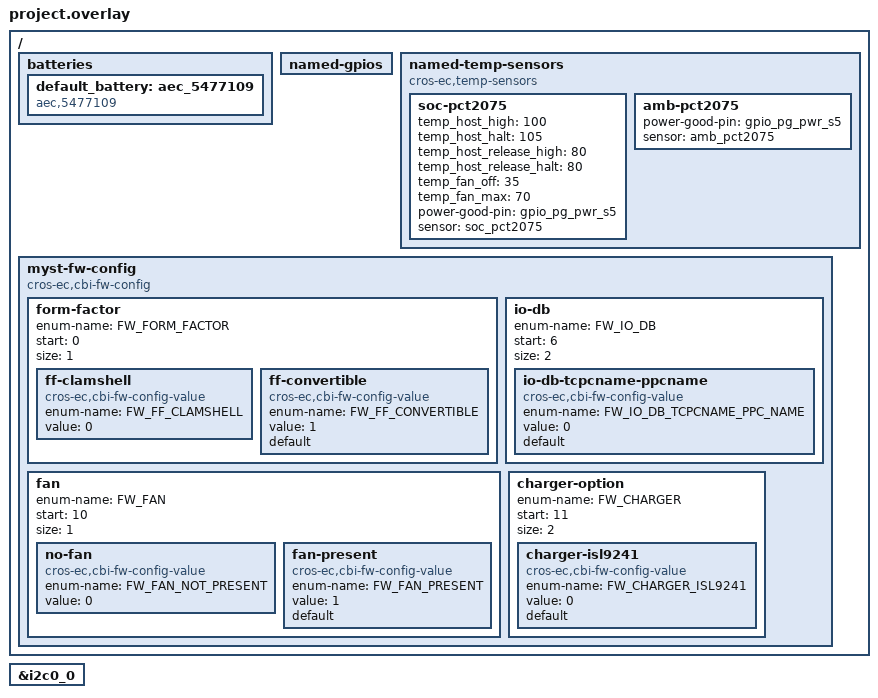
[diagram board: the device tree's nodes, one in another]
/* Copyright 2023 The ChromiumOS Authors
 * Use of this source code is governed by a BSD-style license that can be
 * found in the LICENSE file.
 */

/* Myst program common DTS includes */
#include "../adc.dtsi"
#include "../fan.dtsi"
#include "../gpio.dtsi"
#include "../i2c.dtsi"
#include "../interrupts.dtsi"
#include "../keyboard.dtsi"
#include "../usbc.dtsi"

/* Myst project DTS includes*/
#include "led_pins.dtsi"
#include "led_policy.dtsi"

/* Myst overrides follow... */
/ {
	/* battery overrides */
	batteries {
		default_battery: aec_5477109 {
			compatible = "aec,5477109", "battery-smart";
		};
	};

	named-gpios {
		/* Myst-specific GPIO customizations */
	};

	named-temp-sensors {
		compatible = "cros-ec,temp-sensors";
		soc-pct2075 {
			temp_host_high = <100>;
			temp_host_halt = <105>;
			temp_host_release_high = <80>;
			temp_host_release_halt = <80>;
			temp_fan_off = <35>;
			temp_fan_max = <70>;
			power-good-pin = <&gpio_pg_pwr_s5>;
			sensor = <&soc_pct2075>;
		};
		amb-pct2075 {
			power-good-pin = <&gpio_pg_pwr_s5>;
			sensor = <&amb_pct2075>;
		};
	};

	/*
	 * Note this is expected to vary per-board, so we keep it in the overlay
	 * files.
	 */
	myst-fw-config {
		compatible = "cros-ec,cbi-fw-config";

		form-factor {
			enum-name = "FW_FORM_FACTOR";
			start = <0>;
			size = <1>;

			ff-clamshell {
				compatible = "cros-ec,cbi-fw-config-value";
				enum-name = "FW_FF_CLAMSHELL";
				value = <0>;
			};
			ff-convertible {
				compatible = "cros-ec,cbi-fw-config-value";
				enum-name = "FW_FF_CONVERTIBLE";
				value = <1>;
				default;
			};
		};
		io-db {
			enum-name = "FW_IO_DB";
			start = <6>;
			size = <2>;

			io-db-tcpcname-ppcname {
				compatible = "cros-ec,cbi-fw-config-value";
				enum-name = "FW_IO_DB_TCPCNAME_PPC_NAME";
				value = <0>;
                                default;
			};
		};

		/*
		 * FW_CONFIG field to enable fan or not.
		 */
		fan {
			enum-name = "FW_FAN";
			start = <10>;
			size = <1>;

			no-fan {
				compatible = "cros-ec,cbi-fw-config-value";
				enum-name = "FW_FAN_NOT_PRESENT";
				value = <0>;
			};
			fan-present {
				compatible = "cros-ec,cbi-fw-config-value";
				enum-name = "FW_FAN_PRESENT";
				value = <1>;
				/*
				 * Set as default so that unprovisioned
				 * configs will run the fan regardless.
				 */
				default;
			};
		};

		charger-option {
			enum-name = "FW_CHARGER";
			start = <11>;
			size = <2>;

			charger-isl9241 {
				compatible = "cros-ec,cbi-fw-config-value";
				enum-name = "FW_CHARGER_ISL9241";
				value = <0>;
				default;
			};
		};
	};
};

/* i2c overrides */
&i2c0_0 {
	/delete-node/ nx20p348x@71;
};
